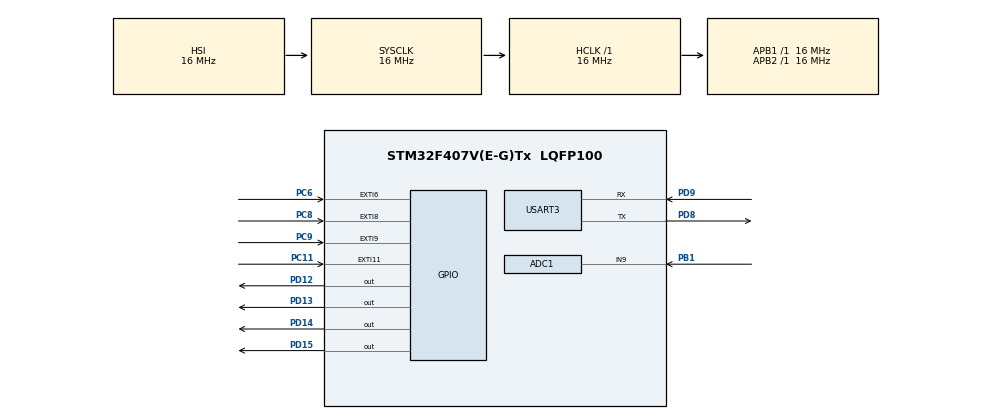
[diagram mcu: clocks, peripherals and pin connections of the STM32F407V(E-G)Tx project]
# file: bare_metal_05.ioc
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ADC1.Channel-0\#ChannelRegularConversion=ADC_CHANNEL_9
ADC1.ClockPrescaler=ADC_CLOCK_SYNC_PCLK_DIV8
ADC1.ContinuousConvMode=DISABLE
ADC1.EOCSelection=ADC_EOC_SINGLE_CONV
ADC1.NbrOfConversionFlag=1
ADC1.Rank-0\#ChannelRegularConversion=1
ADC1.SamplingTime-0\#ChannelRegularConversion=ADC_SAMPLETIME_480CYCLES
ADC1.master=1
Dma.ADC1.0.Direction=DMA_PERIPH_TO_MEMORY
Dma.ADC1.0.FIFOMode=DMA_FIFOMODE_DISABLE
Dma.ADC1.0.Instance=DMA2_Stream0
Dma.ADC1.0.MemDataAlignment=DMA_MDATAALIGN_WORD
Dma.ADC1.0.MemInc=DMA_MINC_ENABLE
Dma.ADC1.0.Mode=DMA_NORMAL
Dma.ADC1.0.PeriphDataAlignment=DMA_PDATAALIGN_WORD
Dma.ADC1.0.PeriphInc=DMA_PINC_DISABLE
Dma.ADC1.0.Priority=DMA_PRIORITY_LOW
Dma.Request0=ADC1
Dma.Request1=USART3_RX
Dma.USART3_RX.1.Direction=DMA_PERIPH_TO_MEMORY
Dma.USART3_RX.1.FIFOMode=DMA_FIFOMODE_DISABLE
Dma.USART3_RX.1.Instance=DMA1_Stream1
Dma.USART3_RX.1.MemDataAlignment=DMA_MDATAALIGN_BYTE
Dma.USART3_RX.1.MemInc=DMA_MINC_ENABLE
Dma.USART3_RX.1.Mode=DMA_NORMAL
Dma.USART3_RX.1.PeriphDataAlignment=DMA_PDATAALIGN_BYTE
Dma.USART3_RX.1.PeriphInc=DMA_PINC_DISABLE
Dma.USART3_RX.1.Priority=DMA_PRIORITY_LOW
Mcu.Family=STM32F4
Mcu.Name=STM32F407V(E-G)Tx
Mcu.Package=LQFP100
NVIC.DMA1_Stream1_IRQn=true\:0\:0\:false\:false\:true\:false\:true\:true
NVIC.DMA2_Stream0_IRQn=true\:0\:0\:false\:false\:true\:false\:true\:true
NVIC.EXTI15_10_IRQn=true\:0\:0\:false\:false\:true\:true\:true\:true
NVIC.EXTI9_5_IRQn=true\:0\:0\:false\:false\:true\:true\:true\:true
NVIC.PriorityGroup=NVIC_PRIORITYGROUP_4
NVIC.TIM4_IRQn=true\:0\:0\:false\:false\:true\:true\:true\:true
PB1.Signal=ADCx_IN9
PC11.Signal=GPXTI11
PC6.Signal=GPXTI6
PC8.Signal=GPXTI8
PC9.Signal=GPXTI9
PD12.Signal=GPIO_Output
PD13.Signal=GPIO_Output
PD14.Signal=GPIO_Output
PD15.Signal=GPIO_Output
PD8.Mode=Asynchronous
PD8.Signal=USART3_TX
PD9.Mode=Asynchronous
PD9.Signal=USART3_RX
ProjectManager.HeapSize=0x200
ProjectManager.StackSize=0x400
ProjectManager.TargetToolchain=STM32CubeIDE
RCC.AHBFreq_Value=16000000
RCC.APB1Freq_Value=16000000
RCC.APB2Freq_Value=16000000
RCC.CortexFreq_Value=16000000
RCC.HSE_VALUE=25000000
RCC.HSI_VALUE=16000000
RCC.LSE_VALUE=32768
RCC.SYSCLKFreq_VALUE=16000000
RCC.VCOOutputFreq_Value=192000000
SH.ADCx_IN9.0=ADC1_IN9,IN9
TIM4.AutoReloadPreload=TIM_AUTORELOAD_PRELOAD_ENABLE
TIM4.Period=5000
TIM4.Prescaler=16000
USART3.VirtualMode=VM_ASYNC
VP_TIM4_VS_ClockSourceINT.Mode=Internal
board=custom

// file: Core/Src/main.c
/* USER CODE BEGIN Header */
/**
  ******************************************************************************
  * @file           : main.c
  * @brief          : Main program body
  ******************************************************************************
  * @attention
  *
  * Copyright (c) 2023 STMicroelectronics.
  * All rights reserved.
  *
  * This software is licensed under terms that can be found in the LICENSE file
  * in the root directory of this software component.
  * If no LICENSE file comes with this software, it is provided AS-IS.
  *
  ******************************************************************************
  */
/* USER CODE END Header */
#include "main.h"

/* USER CODE BEGIN Includes */
#include "app_data.h"
#include "callbacks.h"
/* USER CODE END Includes */

ADC_HandleTypeDef hadc1;
DMA_HandleTypeDef hdma_adc1;

TIM_HandleTypeDef htim4;

UART_HandleTypeDef huart3;
DMA_HandleTypeDef hdma_usart3_rx;

/* USER CODE BEGIN PV */
uint8_t receivedChar;
/* USER CODE END PV */

void SystemClock_Config(void);
static void MX_GPIO_Init(void);
static void MX_DMA_Init(void);
static void MX_USART3_UART_Init(void);
static void MX_ADC1_Init(void);
static void MX_TIM4_Init(void);

int main(void)
{

  /* MCU Configuration--------------------------------------------------------*/

  /* Reset of all peripherals, Initializes the Flash interface and the Systick. */
  HAL_Init();

  /* Configure the system clock */
  SystemClock_Config();

  /* Initialize all configured peripherals */
  MX_GPIO_Init();
  MX_DMA_Init();
  MX_USART3_UART_Init();
  MX_ADC1_Init();
  MX_TIM4_Init();

  /* Infinite loop */
  /* USER CODE BEGIN WHILE */
  HAL_TIM_Base_Start_IT(&htim4);
  while (1)
  {
	HAL_UART_Receive_DMA(&huart3, &receivedChar, 1);
    /* USER CODE END WHILE */

  }
}

void SystemClock_Config(void)
{
  RCC_OscInitTypeDef RCC_OscInitStruct = {0};
  RCC_ClkInitTypeDef RCC_ClkInitStruct = {0};

  /** Configure the main internal regulator output voltage
  */
  __HAL_RCC_PWR_CLK_ENABLE();
  __HAL_PWR_VOLTAGESCALING_CONFIG(PWR_REGULATOR_VOLTAGE_SCALE1);

  /** Initializes the RCC Oscillators according to the specified parameters
  * in the RCC_OscInitTypeDef structure.
  */
  RCC_OscInitStruct.OscillatorType = RCC_OSCILLATORTYPE_HSI;
  RCC_OscInitStruct.HSIState = RCC_HSI_ON;
  RCC_OscInitStruct.HSICalibrationValue = RCC_HSICALIBRATION_DEFAULT;
  RCC_OscInitStruct.PLL.PLLState = RCC_PLL_NONE;
  if (HAL_RCC_OscConfig(&RCC_OscInitStruct) != HAL_OK)
  {
    Error_Handler();
  }

  /** Initializes the CPU, AHB and APB buses clocks
  */
  RCC_ClkInitStruct.ClockType = RCC_CLOCKTYPE_HCLK|RCC_CLOCKTYPE_SYSCLK
                              |RCC_CLOCKTYPE_PCLK1|RCC_CLOCKTYPE_PCLK2;
  RCC_ClkInitStruct.SYSCLKSource = RCC_SYSCLKSOURCE_HSI;
  RCC_ClkInitStruct.AHBCLKDivider = RCC_SYSCLK_DIV1;
  RCC_ClkInitStruct.APB1CLKDivider = RCC_HCLK_DIV1;
  RCC_ClkInitStruct.APB2CLKDivider = RCC_HCLK_DIV1;

  if (HAL_RCC_ClockConfig(&RCC_ClkInitStruct, FLASH_LATENCY_0) != HAL_OK)
  {
    Error_Handler();
  }
}

static void MX_ADC1_Init(void)
{

  ADC_ChannelConfTypeDef sConfig = {0};

  /** Configure the global features of the ADC (Clock, Resolution, Data Alignment and number of conversion)
  */
  hadc1.Instance = ADC1;
  hadc1.Init.ClockPrescaler = ADC_CLOCK_SYNC_PCLK_DIV8;
  hadc1.Init.Resolution = ADC_RESOLUTION_12B;
  hadc1.Init.ScanConvMode = DISABLE;
  hadc1.Init.ContinuousConvMode = DISABLE;
  hadc1.Init.DiscontinuousConvMode = DISABLE;
  hadc1.Init.ExternalTrigConvEdge = ADC_EXTERNALTRIGCONVEDGE_NONE;
  hadc1.Init.ExternalTrigConv = ADC_SOFTWARE_START;
  hadc1.Init.DataAlign = ADC_DATAALIGN_RIGHT;
  hadc1.Init.NbrOfConversion = 1;
  hadc1.Init.DMAContinuousRequests = DISABLE;
  hadc1.Init.EOCSelection = ADC_EOC_SINGLE_CONV;
  if (HAL_ADC_Init(&hadc1) != HAL_OK)
  {
    Error_Handler();
  }

  /** Configure for the selected ADC regular channel its corresponding rank in the sequencer and its sample time.
  */
  sConfig.Channel = ADC_CHANNEL_9;
  sConfig.Rank = 1;
  sConfig.SamplingTime = ADC_SAMPLETIME_480CYCLES;
  if (HAL_ADC_ConfigChannel(&hadc1, &sConfig) != HAL_OK)
  {
    Error_Handler();
  }

}

static void MX_TIM4_Init(void)
{

  TIM_ClockConfigTypeDef sClockSourceConfig = {0};
  TIM_MasterConfigTypeDef sMasterConfig = {0};

  htim4.Instance = TIM4;
  htim4.Init.Prescaler = 16000;
  htim4.Init.CounterMode = TIM_COUNTERMODE_UP;
  htim4.Init.Period = 5000;
  htim4.Init.ClockDivision = TIM_CLOCKDIVISION_DIV1;
  htim4.Init.AutoReloadPreload = TIM_AUTORELOAD_PRELOAD_ENABLE;
  if (HAL_TIM_Base_Init(&htim4) != HAL_OK)
  {
    Error_Handler();
  }
  sClockSourceConfig.ClockSource = TIM_CLOCKSOURCE_INTERNAL;
  if (HAL_TIM_ConfigClockSource(&htim4, &sClockSourceConfig) != HAL_OK)
  {
    Error_Handler();
  }
  sMasterConfig.MasterOutputTrigger = TIM_TRGO_RESET;
  sMasterConfig.MasterSlaveMode = TIM_MASTERSLAVEMODE_DISABLE;
  if (HAL_TIMEx_MasterConfigSynchronization(&htim4, &sMasterConfig) != HAL_OK)
  {
    Error_Handler();
  }

}

static void MX_USART3_UART_Init(void)
{

  huart3.Instance = USART3;
  huart3.Init.BaudRate = 115200;
  huart3.Init.WordLength = UART_WORDLENGTH_8B;
  huart3.Init.StopBits = UART_STOPBITS_1;
  huart3.Init.Parity = UART_PARITY_NONE;
  huart3.Init.Mode = UART_MODE_TX_RX;
  huart3.Init.HwFlowCtl = UART_HWCONTROL_NONE;
  huart3.Init.OverSampling = UART_OVERSAMPLING_16;
  if (HAL_UART_Init(&huart3) != HAL_OK)
  {
    Error_Handler();
  }

}

static void MX_DMA_Init(void)
{

  /* DMA controller clock enable */
  __HAL_RCC_DMA2_CLK_ENABLE();
  __HAL_RCC_DMA1_CLK_ENABLE();

  /* DMA interrupt init */
  /* DMA1_Stream1_IRQn interrupt configuration */
  HAL_NVIC_SetPriority(DMA1_Stream1_IRQn, 0, 0);
  HAL_NVIC_EnableIRQ(DMA1_Stream1_IRQn);
  /* DMA2_Stream0_IRQn interrupt configuration */
  HAL_NVIC_SetPriority(DMA2_Stream0_IRQn, 0, 0);
  HAL_NVIC_EnableIRQ(DMA2_Stream0_IRQn);

}

static void MX_GPIO_Init(void)
{
  GPIO_InitTypeDef GPIO_InitStruct = {0};

  /* GPIO Ports Clock Enable */
  __HAL_RCC_GPIOB_CLK_ENABLE();
  __HAL_RCC_GPIOD_CLK_ENABLE();
  __HAL_RCC_GPIOC_CLK_ENABLE();

  /*Configure GPIO pin Output Level */
  HAL_GPIO_WritePin(GPIOD, GPIO_PIN_12|GPIO_PIN_13|GPIO_PIN_14|GPIO_PIN_15, GPIO_PIN_RESET);

  /*Configure GPIO pins : PD12 PD13 PD14 PD15 */
  GPIO_InitStruct.Pin = GPIO_PIN_12|GPIO_PIN_13|GPIO_PIN_14|GPIO_PIN_15;
  GPIO_InitStruct.Mode = GPIO_MODE_OUTPUT_PP;
  GPIO_InitStruct.Pull = GPIO_NOPULL;
  GPIO_InitStruct.Speed = GPIO_SPEED_FREQ_LOW;
  HAL_GPIO_Init(GPIOD, &GPIO_InitStruct);

  /*Configure GPIO pins : PC6 PC8 PC9 PC11 */
  GPIO_InitStruct.Pin = GPIO_PIN_6|GPIO_PIN_8|GPIO_PIN_9|GPIO_PIN_11;
  GPIO_InitStruct.Mode = GPIO_MODE_IT_RISING;
  GPIO_InitStruct.Pull = GPIO_NOPULL;
  HAL_GPIO_Init(GPIOC, &GPIO_InitStruct);

  /* EXTI interrupt init*/
  HAL_NVIC_SetPriority(EXTI9_5_IRQn, 0, 0);
  HAL_NVIC_EnableIRQ(EXTI9_5_IRQn);

  HAL_NVIC_SetPriority(EXTI15_10_IRQn, 0, 0);
  HAL_NVIC_EnableIRQ(EXTI15_10_IRQn);

}

void Error_Handler(void)
{
  __disable_irq();
  while (1)
  {
  }
}
